# STM32U345 register map
File version: 1.0
CPU: CM33 r0p1, little endian, MPU, FPU, 4 interrupt priority bits
Registers are 32-bit, read-write, reset 0x0 unless marked. A register's access mark holds for its fields unless they carry their own. Offsets are from the block's base; [hi:lo] are bit positions; {n}, {i} and the like mark numbered series.

## GPIOD — GPIOD address block description
Base 0x42020D00
Same registers: GPIOD_S 0x52020D00
0x00 GPIOD_MODER reset 0x30 — Individual bits of this register are protected against nonsecure access when corresponding SECy = 1 in GPIO_SECCFGR and the system is secure (TZEN = 1). Reset: for port H
  [5:4] MODE2 — Port x I/O pin y mode configuration These bits are written by software to configure the I/O mode. Note: This bit field is reserved and must be kept at reset value when the corresponding I/O is not available on the selected package.
    0=Input mode; 1=General purpose output mode; 2=Alternate function mode; 3=Analog mode (reset state)
0x04 GPIOD_OTYPER — Individual bits of this register are protected against nonsecure access when corresponding SECy = 1 in GPIO_SECCFGR and the system is secure (TZEN = 1).
  [2] OT2 — Port x I/O pin y output type configuration These bits are written by software to configure the I/O output type. Note: This bit is reserved and must be kept at reset value when the corresponding I/O is not available on the selected package.
    0=Output push-pull (reset state); 1=Output open-drain
0x08 GPIOD_OSPEEDR — Individual bits of this register are protected against nonsecure access when corresponding SECy = 1 in GPIO_SECCFGR and the system is secure (TZEN = 1). Reset: for the other ports
  [5:4] OSPEED2 — Port x I/O pin y output speed configuration These bits are written by software to configure the I/O output speed. Note: Refer to the device datasheet for the frequency specifications, and the power supply and load conditions for each speed. Note: This bit field is reserved and must be kept at reset value when the corresponding I/O is not available on the selected package.
    0=Low speed; 1=Medium speed; 2=High speed; 3=Very-high speed
0x0C GPIOD_PUPDR — Individual bits of this register are protected against nonsecure access when corresponding SECy = 1 in GPIO_SECCFGR and the system is secure (TZEN = 1). Reset: for the other ports
  [5:4] PUPD2 — Port x I/O pin y pull-up/pull-down configuration These bits are written by software to configure the I/O pull-up or pull-down Note: This bit field is reserved and must be kept at reset value when the corresponding I/O is not available on the selected package.
    0=No pull-up or pull-down; 1=Pull-up; 2=Pull-down
0x10 GPIOD_IDR ro (reset mask 0xFFFF0000) — Individual bits of this register are protected against nonsecure access when corresponding SECy = 1 in GPIO_SECCFGR and the system is secure (TZEN = 1).
  [2] ID2 — Port x I/O pin y input data These bits are read-only. They contain the input value of the corresponding I/O port. Note: This bit is reserved and must be kept at reset value when the corresponding I/O is not available on the selected package.
0x14 GPIOD_ODR — Individual bits of this register are protected against nonsecure access when corresponding SECy = 1 in GPIO_SECCFGR and the system is secure (TZEN = 1).
  [2] OD2 — Port x I/O pin y output data These bits can be read and written by software. Note: For atomic bit set/reset, these bits can be individually set and/or reset by writing to GPIOx_BSRR or GPIOx_BRR. Note: This bit is reserved and must be kept at reset value when the corresponding I/O is not available on the selected package.
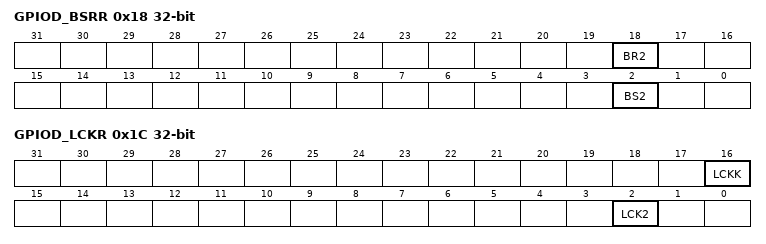
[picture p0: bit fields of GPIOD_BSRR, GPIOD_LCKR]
0x18 GPIOD_BSRR wo — Individual bits of this register are protected against nonsecure access when corresponding SECy = 1 in GPIO_SECCFGR and the system is secure (TZEN = 1).
  [18] BR2 — Port x I/O pin y output reset These bits are write-only. A read to these bits returns the value 0x0000. Note: If both BSy and BRy are set, BSy has priority. Note: This bit is reserved and must be kept at reset value when the corresponding I/O is not available on the selected package.
    0=No action on the corresponding ODy bit; 1=Resets the corresponding ODy bit
  [2] BS2 — Port x I/O pin y output set These bits are write-only. A read to these bits returns the value 0x0000. Note: The bit is reserved and must be kept at reset value when the corresponding I/O is not available on the selected package.
    0=No action on the corresponding ODy bit; 1=Sets the corresponding ODy bit
0x1C GPIOD_LCKR — This register is used to lock the configuration of the port bits when a correct write sequence is applied to bit 16 (LCKK). The value of bits [15:0] is used to lock the configuration of the GPIO. During the write sequence, LCKR[15:0] value must not change. When the LOCK sequence has been applied on a port bit, the value of this port bit can no longer be modified until the next MCU reset or peripheral reset. Each lock bit freezes corresponding configuration bits in configuration and alternate function registers. Individual bits of this register are protected against nonsecure access when corresponding SECy = 1 in GPIO_SECCFGR and the system is secure (TZEN = 1).
  [16] LCKK — Lock key This bit can be read any time. It can only be modified by using the lock key write sequence. LOCK key write sequence: WR LCKR[16] = 1 + LCKR[15:0] WR LCKR[16] = 0 + LCKR[15:0] WR LCKR[16] = 1 + LCKR[15:0] LOCK key read RD LCKR[16] = 1 (this read operation is optional but it confirms that the lock is active) Note: During the lock key write sequence, the value of LCK[15:0] must not change. Note: Any error in the lock sequence aborts the LOCK. Note: After the first lock sequence on any bit of the port, any read access on the LCKK bit returns 1 until the next MCU reset or peripheral reset.
    0=Port configuration lock key not active; 1=Port configuration lock key active. The GPIOx_LCKR register is locked until the next MCU reset or peripheral reset.
  [2] LCK2 — Port x I/O pin y lock These bits are read/write but can only be written when LCKK = 0. Note: This bit is reserved and must be kept at reset value when the corresponding I/O is not available on the selected package.
    0=Port configuration not locked; 1=Port configuration locked
0x20 GPIOD_AFRL — Individual bits of this register are protected against nonsecure access when corresponding SECy = 1 in GPIO_SECCFGR and the system is secure (TZEN = 1).
  [11:8] AFSEL2 — Port x I/O pin y alternate function selection for These bits are written by software to configure alternate function I/Os. Note: This bit field is reserved and must be kept at reset value when the corresponding I/O is not available on the selected package.
    {v}=AF{v} (v=0..15)
0x28 GPIOD_BRR wo — Individual bits of this register are protected against nonsecure access when corresponding SECy = 1 in GPIO_SECCFGR and the system is secure (TZEN = 1).
  [2] BR2 — Port x I/O pin y output reset These bits are write-only. A read to these bits returns the value 0x0000. Note: This bit is reserved and must be kept at reset value when the corresponding I/O is not available on the selected package.
    0=No action on the corresponding ODy bit; 1=Reset the corresponding ODy bit
0x2C GPIOD_HSLVR — Individual bits of this register are protected against nonsecure access when corresponding SECy = 1 in GPIO_SECCFGR and the system is secure (TZEN = 1).
  [2] HSLV2 — Port x I/O pin y high-speed low-voltage configuration These bits are written by software to optimize the I/O speed when the I/O supply is low. Each bit is active only if the corresponding IO_VDD_HSLV/IO_VDDIO2_HSLV user option bit is set. It must be used only if the I/O supply voltage is below 2.7 V. Setting these bits when the I/O supply (V<sub>DD</sub> or V<sub>DDIO2</sub>) is higher than 2.7 V may be destructive. Setting this bit when the I/O is configured in Fm+ mode is forbidden. Note: Not all I/Os support the HSLV mode. Refer to the I/O structure in the corresponding datasheet for the list of I/Os supporting this feature. HSLV configuration for the other I/Os must be kept at reset value. Note: This bit is reserved and must be kept at reset value when the corresponding I/O is not available on the selected package.
    0=I/O speed optimization disabled; 1=I/O speed optimization enabled
0x30 GPIOD_SECCFGR reset 0xB — When the system is secure (TZEN = 1), this register is used to configure selected I/O pin as secure. It can be written only by a secure access. A nonsecure write access to this register is ignored. Both nonsecure and secure reads return the register data. When the system is not secure (TZEN = 0), this register is RAZ/WI. Reset: for port H
  [2] SEC2 — Port x I/O pin y security configuration These bits are written by software to enable or disable the I/O port pin security. Note: The bit is reserved and must be kept to reset value when the corresponding I/O is not available on the selected package.
    0=The I/O pin is nonsecure; 1=The I/O pin is secure. Refer to Table 111: GPIO secured bits for all corresponding secured bits.
